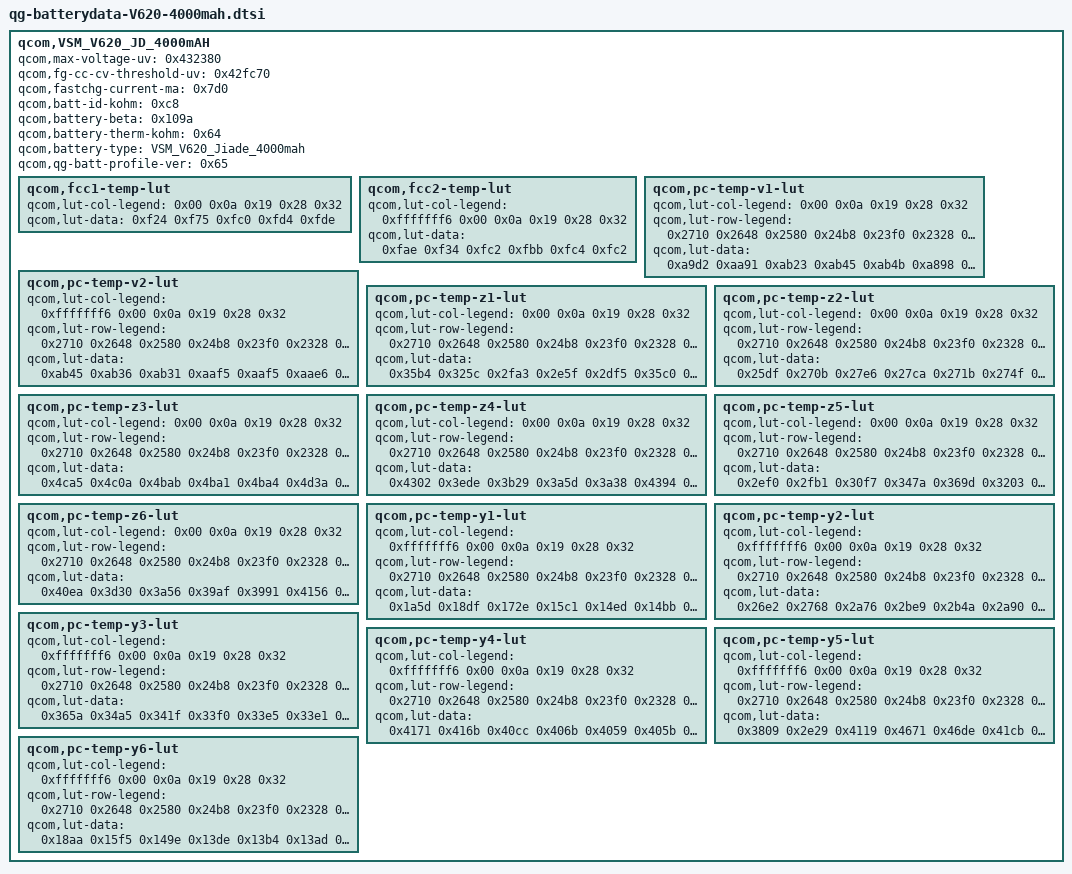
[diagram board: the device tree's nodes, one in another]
qcom,VSM_V620_JD_4000mAH {
	qcom,max-voltage-uv = <0x432380>;
	qcom,fg-cc-cv-threshold-uv = <0x42fc70>;
	qcom,fastchg-current-ma = <0x7d0>;
	qcom,batt-id-kohm = <0xc8>;
	qcom,battery-beta = <0x109a>;
	qcom,battery-therm-kohm = <0x64>;
	qcom,battery-type = "VSM_V620_Jiade_4000mah";
	qcom,qg-batt-profile-ver = <0x65>;

	qcom,fcc1-temp-lut {
		qcom,lut-col-legend = <0x00 0x0a 0x19 0x28 0x32>;
		qcom,lut-data = <0xf24 0xf75 0xfc0 0xfd4 0xfde>;
	};

	qcom,fcc2-temp-lut {
		qcom,lut-col-legend = <0xfffffff6 0x00 0x0a 0x19 0x28 0x32>;
		qcom,lut-data = <0xfae 0xf34 0xfc2 0xfbb 0xfc4 0xfc2>;
	};

	qcom,pc-temp-v1-lut {
		qcom,lut-col-legend = <0x00 0x0a 0x19 0x28 0x32>;
		qcom,lut-row-legend = <0x2710 0x2648 0x2580 0x24b8 0x23f0 0x2328 0x2260 0x2198 0x20d0 0x2008 0x1f40 0x1e78 0x1db0 0x1ce8 0x1c20 0x1b58 0x1a90 0x19c8 0x1900 0x1838 0x1770 0x16a8 0x15e0 0x1518 0x1450 0x1388 0x12c0 0x11f8 0x1130 0x1068 0xfa0 0xed8 0xe10 0xd48 0xc80 0xbb8 0xaf0 0xa28 0x960 0x898 0x7d0 0x708 0x640 0x578 0x4b0 0x3e8 0x384 0x320 0x2bc 0x258 0x1f4 0x190 0x12c 0xc8 0x64 0x00>;
		qcom,lut-data = <0xa9d2 0xaa91 0xab23 0xab45 0xab4b 0xa898 0xa95b 0xa9ce 0xa9e6 0xa9e6 0xa78e 0xa83d 0xa8b3 0xa8c9 0xa8ca 0xa69d 0xa73a 0xa7ab 0xa7c5 0xa7c7 0xa5b4 0xa647 0xa6af 0xa6c9 0xa6cc 0xa4d1 0xa55a 0xa5bd 0xa5d8 0xa5db 0xa3f6 0xa471 0xa4ce 0xa4eb 0xa4f0 0xa31e 0xa390 0xa3e1 0xa3ff 0xa406 0xa24b 0xa2b4 0xa2fb 0xa319 0xa321 0xa188 0xa1e0 0xa218 0xa238 0xa23f 0xa0e0 0xa11e 0xa13d 0xa15b 0xa15f 0xa032 0xa078 0xa07a 0xa085 0xa088 0x9f4b 0x9fc4 0x9fcb 0x9fb7 0x9fb7 0x9e26 0x9ecb 0x9f08 0x9eef 0x9eee 0x9d22 0x9da6 0x9e0e 0x9e25 0x9e29 0x9c65 0x9cca 0x9d18 0x9d62 0x9d6a 0x9bc7 0x9c30 0x9c6d 0x9cb0 0x9cb6 0x9b43 0x9bab 0x9be6 0x9c0b 0x9c0b 0x9ad2 0x9b2c 0x9b5e 0x9b6c 0x9b67 0x9a64 0x9ab3 0x9ad5 0x9adc 0x9ad4 0x99ed 0x9a35 0x9a43 0x9a4b 0x9a43 0x9974 0x99b4 0x9992 0x9992 0x998d 0x98fe 0x9924 0x98c6 0x98a7 0x98a3 0x988e 0x9856 0x9808 0x97dc 0x97d8 0x9820 0x9759 0x974b 0x9743 0x9744 0x97ad 0x96ae 0x96ae 0x96c4 0x96c8 0x9737 0x964a 0x9653 0x965e 0x965c 0x96c9 0x9603 0x9613 0x960a 0x95fa 0x9662 0x95d1 0x95d3 0x95bb 0x95a4 0x9606 0x95ab 0x9592 0x956e 0x955a 0x95c3 0x9588 0x9557 0x9529 0x9517 0x958b 0x9566 0x951f 0x94ec 0x94d9 0x9562 0x9544 0x94ed 0x94b8 0x94a0 0x9547 0x9524 0x94c1 0x9487 0x946a 0x9532 0x9508 0x94a0 0x945c 0x943a 0x951a 0x94e9 0x947e 0x9433 0x940b 0x9500 0x94cb 0x945a 0x9407 0x93d8 0x94df 0x94a7 0x9434 0x93d9 0x93a4 0x94b2 0x9474 0x9401 0x939e 0x9362 0x9474 0x942b 0x93b6 0x934c 0x930a 0x9425 0x93d2 0x935c 0x92ec 0x92a6 0x93ac 0x9362 0x92f3 0x9286 0x923d 0x9320 0x92dc 0x9275 0x9210 0x91c4 0x9282 0x923b 0x91d6 0x9172 0x9124 0x91ee 0x91a1 0x9141 0x90e4 0x9097 0x9180 0x9137 0x90d6 0x9084 0x9045 0x915a 0x9110 0x90b5 0x9062 0x9029 0x9143 0x90f8 0x90a0 0x904d 0x9012 0x9129 0x90e5 0x908e 0x903a 0x8ffe 0x9102 0x90c8 0x9070 0x9019 0x8fd5 0x907f 0x903a 0x8fca 0x8f56 0x8ef0 0x8ee2 0x8e98 0x8e2c 0x8db2 0x8d48 0x8cae 0x8c65 0x8bf8 0x8b7c 0x8b12 0x89ae 0x8964 0x88f2 0x8879 0x8808 0x84f4 0x84af 0x8440 0x83d1 0x8353 0x7530 0x7530 0x7530 0x7530 0x7530>;
	};

	qcom,pc-temp-v2-lut {
		qcom,lut-col-legend = <0xfffffff6 0x00 0x0a 0x19 0x28 0x32>;
		qcom,lut-row-legend = <0x2710 0x2648 0x2580 0x24b8 0x23f0 0x2328 0x2260 0x2198 0x20d0 0x2008 0x1f40 0x1e78 0x1db0 0x1ce8 0x1c20 0x1b58 0x1a90 0x19c8 0x1900 0x1838 0x1770 0x16a8 0x15e0 0x1518 0x1450 0x1388 0x12c0 0x11f8 0x1130 0x1068 0xfa0 0xed8 0xe10 0xd48 0xc80 0xbb8 0xaf0 0xa28 0x960 0x898 0x7d0 0x708 0x640 0x578 0x4b0 0x3e8 0x384 0x320 0x2bc 0x258 0x1f4 0x190 0x12c 0xc8 0x64 0x00>;
		qcom,lut-data = <0xab45 0xab36 0xab31 0xaaf5 0xaaf5 0xaae6 0xa97d 0xa997 0xa9af 0xa982 0xa98a 0xa97f 0xa7ee 0xa82a 0xa857 0xa835 0xa843 0xa83c 0xa6a0 0xa6f8 0xa730 0xa715 0xa727 0xa721 0xa584 0xa5f7 0xa632 0xa61e 0xa62f 0xa62b 0xa48d 0xa509 0xa53f 0xa530 0xa541 0xa53d 0xa3c0 0xa41d 0xa44c 0xa442 0xa452 0xa44f 0xa303 0xa33a 0xa360 0xa358 0xa369 0xa365 0xa221 0xa258 0xa27c 0xa273 0xa283 0xa27f 0xa115 0xa16d 0xa19c 0xa190 0xa1a0 0xa19d 0xa035 0xa096 0xa0ca 0xa0b7 0xa0c3 0xa0c0 0x9fb0 0x9ffa 0xa016 0x9ff1 0x9fed 0x9fe9 0x9f35 0x9f7f 0x9f64 0x9f2f 0x9f1d 0x9f18 0x9e35 0x9ecf 0x9e84 0x9e56 0x9e53 0x9e4e 0x9c4a 0x9dad 0x9d75 0x9d66 0x9d8e 0x9d8b 0x9ad2 0x9c78 0x9c90 0x9c96 0x9cd3 0x9cd0 0x9a32 0x9b8d 0x9be9 0x9bf7 0x9c23 0x9c1f 0x99b6 0x9adf 0x9b4f 0x9b68 0x9b7b 0x9b75 0x9913 0x9a33 0x9a9b 0x9ad9 0x9adc 0x9ad6 0x9851 0x995b 0x99d3 0x9a4e 0x9a49 0x9a40 0x979f 0x982c 0x990e 0x99ad 0x99a5 0x999e 0x9705 0x96fb 0x9847 0x98ce 0x98e3 0x98e4 0x967b 0x963c 0x978d 0x97e5 0x981a 0x9822 0x9603 0x95c9 0x96f2 0x972e 0x975c 0x9764 0x9596 0x9558 0x9669 0x968f 0x96a4 0x96a7 0x953d 0x94f9 0x95f1 0x960c 0x9613 0x9612 0x94f8 0x94b9 0x9587 0x95a2 0x95a6 0x95a4 0x94bc 0x9497 0x9526 0x9546 0x954a 0x9547 0x9484 0x9461 0x94c9 0x94f1 0x94f6 0x94ef 0x9451 0x9436 0x9470 0x94a5 0x94aa 0x94a0 0x9421 0x940f 0x942c 0x945f 0x9468 0x945b 0x93f2 0x93ec 0x93f8 0x941e 0x942e 0x9420 0x93c5 0x93ca 0x93cd 0x93e5 0x93f6 0x93e7 0x9393 0x93a9 0x93aa 0x93b3 0x93bc 0x93ab 0x9361 0x9389 0x938e 0x9389 0x9382 0x936d 0x932c 0x9363 0x936c 0x935c 0x9340 0x9325 0x92f3 0x9335 0x9349 0x932e 0x92f6 0x92cb 0x92b8 0x92fd 0x9320 0x92fc 0x92a8 0x9270 0x9278 0x92bb 0x92ea 0x92bb 0x925d 0x921f 0x9236 0x9270 0x92a7 0x926e 0x9212 0x91d3 0x91f3 0x921f 0x9256 0x921c 0x91c4 0x9183 0x91ae 0x91c0 0x91ec 0x91c3 0x9171 0x9133 0x9166 0x915c 0x9175 0x9157 0x9107 0x90c7 0x911e 0x90f5 0x90f2 0x90c9 0x9077 0x9032 0x90cd 0x908f 0x9083 0x904b 0x9006 0x8fce 0x9068 0x9029 0x901b 0x9004 0x8fc8 0x8f92 0x902d 0x8ffb 0x8ffd 0x8ff5 0x8fbc 0x8f88 0x8fe8 0x8fcc 0x8fdb 0x8fe7 0x8fb0 0x8f7a 0x8f93 0x8f91 0x8fa4 0x8fcc 0x8f9a 0x8f62 0x8f06 0x8f2f 0x8f55 0x8f92 0x8f5d 0x8f1a 0x8e10 0x8e62 0x8e99 0x8eb1 0x8e58 0x8df1 0x8c70 0x8ccc 0x8ce7 0x8cee 0x8c7c 0x8c0a 0x8a02 0x8a67 0x8a71 0x8a83 0x8a03 0x8981 0x86a7 0x8706 0x8721 0x8749 0x86b6 0x861f 0x81b8 0x8212 0x822e 0x827f 0x81fb 0x8145 0x70a3 0x6f54 0x6f5b 0x6f90 0x720a 0x70b1>;
	};

	qcom,pc-temp-z1-lut {
		qcom,lut-col-legend = <0x00 0x0a 0x19 0x28 0x32>;
		qcom,lut-row-legend = <0x2710 0x2648 0x2580 0x24b8 0x23f0 0x2328 0x2260 0x2198 0x20d0 0x2008 0x1f40 0x1e78 0x1db0 0x1ce8 0x1c20 0x1b58 0x1a90 0x19c8 0x1900 0x1838 0x1770 0x16a8 0x15e0 0x1518 0x1450 0x1388 0x12c0 0x11f8 0x1130 0x1068 0xfa0 0xed8 0xe10 0xd48 0xc80 0xbb8 0xaf0 0xa28 0x960 0x898 0x7d0 0x708 0x640 0x578 0x4b0 0x3e8 0x384 0x320 0x2bc 0x258 0x1f4 0x190 0x12c 0xc8 0x64 0x00>;
		qcom,lut-data = <0x35b4 0x325c 0x2fa3 0x2e5f 0x2df5 0x35c0 0x3265 0x2fbe 0x2e97 0x2e31 0x35b8 0x326c 0x2fbf 0x2e97 0x2e33 0x35b1 0x3272 0x2fbe 0x2e93 0x2e32 0x35b0 0x3277 0x2fb9 0x2e8c 0x2e30 0x35af 0x3272 0x2fb2 0x2e83 0x2e2d 0x35ae 0x325c 0x2fb3 0x2e7d 0x2e2a 0x35a4 0x3248 0x2fb8 0x2e7a 0x2e29 0x358e 0x323e 0x2fbb 0x2e78 0x2e28 0x3582 0x3236 0x2faa 0x2e77 0x2e27 0x3587 0x322f 0x2f97 0x2e75 0x2e25 0x358f 0x3226 0x2f92 0x2e74 0x2e24 0x357f 0x321e 0x2f8f 0x2e72 0x2e23 0x3543 0x3210 0x2f8b 0x2e70 0x2e23 0x3518 0x31f7 0x2f7f 0x2e6f 0x2e23 0x350c 0x31ed 0x2f74 0x2e6e 0x2e24 0x3505 0x31ef 0x2f74 0x2e6e 0x2e25 0x3502 0x31f3 0x2f7b 0x2e70 0x2e26 0x34fc 0x31fc 0x2f81 0x2e71 0x2e28 0x34f6 0x3209 0x2f89 0x2e74 0x2e29 0x34ef 0x3213 0x2f8f 0x2e77 0x2e2b 0x34ea 0x321c 0x2f91 0x2e78 0x2e2c 0x34f0 0x3222 0x2f91 0x2e79 0x2e2e 0x3502 0x3223 0x2f92 0x2e7a 0x2e30 0x3517 0x3225 0x2f95 0x2e7c 0x2e31 0x3526 0x3227 0x2f99 0x2e7f 0x2e33 0x3535 0x3229 0x2f9d 0x2e83 0x2e35 0x353e 0x322d 0x2fa0 0x2e87 0x2e3a 0x3538 0x3236 0x2fa4 0x2e8b 0x2e3e 0x3530 0x3246 0x2fa8 0x2e8e 0x2e41 0x353d 0x324e 0x2fac 0x2e91 0x2e43 0x3560 0x324f 0x2fb1 0x2e95 0x2e46 0x3572 0x3251 0x2fb6 0x2e99 0x2e49 0x3568 0x3254 0x2fbc 0x2e9d 0x2e4d 0x355c 0x325a 0x2fc5 0x2ea1 0x2e51 0x3561 0x3261 0x2fcc 0x2ea6 0x2e55 0x3583 0x327a 0x2fd1 0x2eab 0x2e58 0x35a3 0x3295 0x2fd5 0x2eaf 0x2e5b 0x35b4 0x329c 0x2fda 0x2eb4 0x2e5f 0x35c0 0x329d 0x2fdf 0x2eb9 0x2e63 0x35c8 0x32a1 0x2fe5 0x2ebd 0x2e66 0x35ca 0x32b3 0x2fee 0x2ec1 0x2e6a 0x35cc 0x32c0 0x2ff7 0x2ec4 0x2e6d 0x35cd 0x32b8 0x2ffa 0x2eca 0x2e70 0x35db 0x32c4 0x3001 0x2ecf 0x2e73 0x35ff 0x32cb 0x300d 0x2ed2 0x2e75 0x35d9 0x32be 0x3006 0x2ecf 0x2e76 0x35e1 0x32b3 0x300f 0x2ed0 0x2e76 0x35e6 0x32b6 0x3011 0x2ed3 0x2e78 0x3603 0x32ca 0x3013 0x2edc 0x2e7e 0x35d7 0x32ea 0x301b 0x2ee2 0x2e85 0x3621 0x32d6 0x3027 0x2eed 0x2e8d 0x360b 0x3305 0x303d 0x2ef4 0x2e96 0x3647 0x3332 0x3050 0x2f0b 0x2ea5 0x3647 0x3332 0x3050 0x2f0b 0x2ea5 0x3647 0x3332 0x3050 0x2f0b 0x2ea5>;
	};

	qcom,pc-temp-z2-lut {
		qcom,lut-col-legend = <0x00 0x0a 0x19 0x28 0x32>;
		qcom,lut-row-legend = <0x2710 0x2648 0x2580 0x24b8 0x23f0 0x2328 0x2260 0x2198 0x20d0 0x2008 0x1f40 0x1e78 0x1db0 0x1ce8 0x1c20 0x1b58 0x1a90 0x19c8 0x1900 0x1838 0x1770 0x16a8 0x15e0 0x1518 0x1450 0x1388 0x12c0 0x11f8 0x1130 0x1068 0xfa0 0xed8 0xe10 0xd48 0xc80 0xbb8 0xaf0 0xa28 0x960 0x898 0x7d0 0x708 0x640 0x578 0x4b0 0x3e8 0x384 0x320 0x2bc 0x258 0x1f4 0x190 0x12c 0xc8 0x64 0x00>;
		qcom,lut-data = <0x25df 0x270b 0x27e6 0x27ca 0x271b 0x274f 0x2795 0x27e3 0x2821 0x2794 0x27b6 0x27ce 0x2830 0x2829 0x27d4 0x27e5 0x27c3 0x2856 0x2828 0x2803 0x27e9 0x27a3 0x283d 0x2825 0x280f 0x27d6 0x2787 0x2814 0x281d 0x2815 0x27c7 0x276e 0x27f8 0x2814 0x2813 0x27bb 0x275a 0x27df 0x27fc 0x27fb 0x27aa 0x274a 0x27d6 0x27e7 0x27e5 0x279d 0x273d 0x27dc 0x27e5 0x27de 0x2796 0x273a 0x27e6 0x27e9 0x27d2 0x2789 0x273d 0x27ee 0x27ea 0x27ce 0x2774 0x2745 0x27f8 0x27ea 0x27b9 0x2759 0x2754 0x2802 0x27eb 0x27aa 0x2745 0x276c 0x2815 0x27f2 0x27ba 0x273b 0x277f 0x2825 0x27f9 0x27d6 0x2730 0x278b 0x2828 0x27ef 0x27d8 0x272a 0x2797 0x2828 0x27cb 0x27ba 0x272b 0x27ad 0x282b 0x27b5 0x27a5 0x272b 0x27c9 0x2841 0x27c1 0x27aa 0x2724 0x27e8 0x2865 0x27de 0x27b7 0x271d 0x280f 0x2897 0x2825 0x27f5 0x271a 0x282e 0x28db 0x28ec 0x28dd 0x2720 0x2837 0x28ed 0x2954 0x2964 0x272d 0x2836 0x28a9 0x28d3 0x28f0 0x273e 0x2836 0x2865 0x282c 0x284f 0x2756 0x283d 0x2866 0x282e 0x2861 0x276a 0x2845 0x2874 0x2881 0x2903 0x277c 0x284f 0x287b 0x28ae 0x2954 0x278c 0x285c 0x287f 0x2896 0x28ca 0x2799 0x2861 0x2882 0x286e 0x2809 0x27a9 0x2866 0x2886 0x2849 0x27b2 0x27b5 0x286c 0x288e 0x2812 0x2778 0x27bb 0x286f 0x288f 0x27fb 0x2766 0x27c0 0x2878 0x288b 0x2801 0x276b 0x27c9 0x287f 0x288a 0x280d 0x2774 0x27d9 0x288a 0x2892 0x281a 0x2797 0x27ee 0x289b 0x289f 0x2830 0x27e2 0x280a 0x28ac 0x28af 0x284d 0x280f 0x282d 0x28be 0x28c7 0x2884 0x282a 0x2848 0x28ca 0x28d6 0x28ab 0x2839 0x2859 0x28d2 0x28d6 0x289a 0x2831 0x2870 0x28d9 0x28d6 0x287c 0x2823 0x2894 0x28dd 0x28d4 0x289e 0x2865 0x2977 0x2948 0x28ed 0x289e 0x287c 0x29ca 0x298b 0x28f6 0x2864 0x2835 0x29a1 0x298d 0x28e2 0x285f 0x2831 0x278f 0x29a5 0x28f9 0x2861 0x2834 0x2710 0x29e8 0x28f6 0x2879 0x284e 0x2734 0x2c60 0x2912 0x28cf 0x28b9 0x280e 0x2b7d 0x2917 0x2874 0x2842 0x2840 0x29ca 0x28c5 0x27f1 0x279d 0x276a 0x292e 0x28af 0x27be 0x2750 0x27d0 0x28c4 0x2861 0x2781 0x271c 0x27d0 0x28c4 0x2861 0x2781 0x271c 0x27d0 0x28c4 0x2861 0x2781 0x271c>;
	};

	qcom,pc-temp-z3-lut {
		qcom,lut-col-legend = <0x00 0x0a 0x19 0x28 0x32>;
		qcom,lut-row-legend = <0x2710 0x2648 0x2580 0x24b8 0x23f0 0x2328 0x2260 0x2198 0x20d0 0x2008 0x1f40 0x1e78 0x1db0 0x1ce8 0x1c20 0x1b58 0x1a90 0x19c8 0x1900 0x1838 0x1770 0x16a8 0x15e0 0x1518 0x1450 0x1388 0x12c0 0x11f8 0x1130 0x1068 0xfa0 0xed8 0xe10 0xd48 0xc80 0xbb8 0xaf0 0xa28 0x960 0x898 0x7d0 0x708 0x640 0x578 0x4b0 0x3e8 0x384 0x320 0x2bc 0x258 0x1f4 0x190 0x12c 0xc8 0x64 0x00>;
		qcom,lut-data = <0x4ca5 0x4c0a 0x4bab 0x4ba1 0x4ba4 0x4d3a 0x4c85 0x4c04 0x4bd5 0x4bc4 0x4d38 0x4cc5 0x4c20 0x4be3 0x4bd2 0x4d22 0x4cd1 0x4c29 0x4bea 0x4bd9 0x4d04 0x4cd7 0x4c29 0x4bf0 0x4be0 0x4cdd 0x4cd7 0x4c27 0x4bf4 0x4be6 0x4cc6 0x4cd3 0x4c25 0x4bf5 0x4be7 0x4cc6 0x4ccc 0x4c22 0x4bf3 0x4be5 0x4ccd 0x4cc4 0x4c1f 0x4bf0 0x4be1 0x4cd6 0x4cba 0x4c1a 0x4be9 0x4bdc 0x4cdf 0x4cad 0x4c13 0x4bdf 0x4bd7 0x4ce9 0x4c99 0x4c07 0x4bd8 0x4bd2 0x4cfd 0x4c89 0x4bf4 0x4bd2 0x4bcc 0x4d23 0x4c86 0x4bec 0x4bce 0x4bc7 0x4d39 0x4c88 0x4bf6 0x4bcd 0x4bc4 0x4d2a 0x4c85 0x4c01 0x4bcd 0x4bc1 0x4d09 0x4c75 0x4bfe 0x4bca 0x4bbd 0x4cee 0x4c60 0x4bf0 0x4bc1 0x4bb8 0x4cd6 0x4c52 0x4be5 0x4bb9 0x4bb3 0x4cc8 0x4c46 0x4bdd 0x4bb3 0x4bad 0x4cc9 0x4c41 0x4bd8 0x4bae 0x4ba7 0x4cce 0x4c3f 0x4bde 0x4bb1 0x4ba8 0x4cd2 0x4c3d 0x4bef 0x4bc2 0x4bb3 0x4cd7 0x4c45 0x4bf5 0x4bca 0x4bba 0x4cdb 0x4c56 0x4bed 0x4bbb 0x4bad 0x4cdf 0x4c5d 0x4be3 0x4ba7 0x4b9b 0x4ce7 0x4c5b 0x4be1 0x4ba9 0x4ba4 0x4cec 0x4c59 0x4bdf 0x4bb9 0x4bd1 0x4ced 0x4c57 0x4bdf 0x4bc7 0x4be7 0x4cec 0x4c54 0x4bea 0x4bd4 0x4be1 0x4ce8 0x4c52 0x4bf5 0x4bdd 0x4bd6 0x4ce3 0x4c51 0x4bf8 0x4bdc 0x4bce 0x4cdc 0x4c4f 0x4bfb 0x4bd4 0x4bc6 0x4cd1 0x4c4e 0x4bfb 0x4bcd 0x4bbe 0x4cc4 0x4c4a 0x4bf5 0x4bc5 0x4bb5 0x4cb7 0x4c46 0x4bed 0x4bbe 0x4bad 0x4ca9 0x4c43 0x4be9 0x4bb8 0x4ba6 0x4c9c 0x4c3f 0x4be5 0x4bb2 0x4ba1 0x4c91 0x4c3c 0x4be1 0x4bb0 0x4b9f 0x4c85 0x4c38 0x4bde 0x4bb0 0x4b9f 0x4c80 0x4c33 0x4bdb 0x4bb1 0x4b9f 0x4c7e 0x4c2e 0x4bd7 0x4bae 0x4b9f 0x4c7c 0x4c29 0x4bd3 0x4bab 0x4ba1 0x4c71 0x4c26 0x4bd3 0x4baf 0x4ba6 0x4c31 0x4c12 0x4bce 0x4bab 0x4ba7 0x4bc9 0x4bf4 0x4bc2 0x4ba2 0x4b9d 0x4bb1 0x4bf2 0x4bc1 0x4b9e 0x4b95 0x4b5b 0x4be6 0x4bb9 0x4b94 0x4b8c 0x4b44 0x4bb5 0x4baa 0x4b90 0x4b87 0x4b47 0x4b77 0x4ba4 0x4b81 0x4b79 0x4b44 0x4b83 0x4ba5 0x4b99 0x4b92 0x4b75 0x4bd7 0x4baa 0x4ba4 0x4ba3 0x4b7d 0x4bca 0x4ba0 0x4ba7 0x4ba0 0x4b99 0x4bc4 0x4ba1 0x4ba6 0x4ba3 0x4b99 0x4bc4 0x4ba1 0x4ba6 0x4ba3 0x4b99 0x4bc4 0x4ba1 0x4ba6 0x4ba3>;
	};

	qcom,pc-temp-z4-lut {
		qcom,lut-col-legend = <0x00 0x0a 0x19 0x28 0x32>;
		qcom,lut-row-legend = <0x2710 0x2648 0x2580 0x24b8 0x23f0 0x2328 0x2260 0x2198 0x20d0 0x2008 0x1f40 0x1e78 0x1db0 0x1ce8 0x1c20 0x1b58 0x1a90 0x19c8 0x1900 0x1838 0x1770 0x16a8 0x15e0 0x1518 0x1450 0x1388 0x12c0 0x11f8 0x1130 0x1068 0xfa0 0xed8 0xe10 0xd48 0xc80 0xbb8 0xaf0 0xa28 0x960 0x898 0x7d0 0x708 0x640 0x578 0x4b0 0x3e8 0x384 0x320 0x2bc 0x258 0x1f4 0x190 0x12c 0xc8 0x64 0x00>;
		qcom,lut-data = <0x4302 0x3ede 0x3b29 0x3a5d 0x3a38 0x4394 0x3e16 0x3be0 0x3ab7 0x3a60 0x4248 0x3d52 0x3b42 0x3a7e 0x3a42 0x409a 0x3c7e 0x3ab4 0x3a36 0x3a15 0x3f66 0x3bb4 0x3a68 0x3a0b 0x39f4 0x3e88 0x3b31 0x3a2d 0x39e6 0x39d7 0x3dd3 0x3ad1 0x3a01 0x39c9 0x39be 0x3d3b 0x3a88 0x39de 0x39ae 0x39a7 0x3cb9 0x3a54 0x39c4 0x399c 0x3996 0x3c42 0x3a2a 0x39b0 0x3995 0x3990 0x3bcd 0x3a04 0x39a1 0x3990 0x398c 0x3b67 0x39db 0x3995 0x3989 0x3987 0x3b1b 0x39c0 0x398b 0x3982 0x3982 0x3ae0 0x39bb 0x3988 0x397b 0x397d 0x3ab2 0x39bb 0x3989 0x3976 0x3978 0x3a91 0x39b8 0x398b 0x3970 0x3973 0x3a75 0x39ab 0x3984 0x396d 0x396f 0x3a58 0x399a 0x3970 0x3969 0x396b 0x3a3d 0x398e 0x3966 0x3965 0x3966 0x3a25 0x3983 0x3962 0x395f 0x395f 0x3a0e 0x397e 0x3961 0x3959 0x3958 0x39f5 0x397b 0x396a 0x3962 0x3961 0x39e1 0x397a 0x3989 0x3994 0x3996 0x39d0 0x399d 0x39ac 0x39c1 0x39c4 0x39c2 0x39f8 0x39e4 0x39e5 0x39e0 0x39ba 0x3a22 0x3a0f 0x3a01 0x39f6 0x39ba 0x3a25 0x3a0a 0x39fa 0x39e8 0x39c1 0x3a21 0x39f2 0x39d4 0x39a6 0x39cc 0x3a14 0x39da 0x39b1 0x397f 0x39d8 0x39fa 0x39bf 0x3996 0x3977 0x39db 0x39e2 0x39a6 0x3980 0x3973 0x39d7 0x39ce 0x3996 0x3976 0x396e 0x39d0 0x39bc 0x3989 0x3970 0x396a 0x39c5 0x39ac 0x3980 0x396c 0x3966 0x39b8 0x399e 0x397a 0x3969 0x3964 0x39ad 0x3992 0x3976 0x3967 0x3962 0x39a5 0x3987 0x3973 0x3967 0x3962 0x399e 0x397f 0x3971 0x3967 0x3962 0x3996 0x397d 0x3971 0x3967 0x3964 0x398f 0x397c 0x3974 0x396f 0x396f 0x398b 0x397b 0x3976 0x3975 0x3979 0x3989 0x3978 0x3972 0x3971 0x3973 0x3986 0x3975 0x396b 0x3968 0x3969 0x3981 0x396f 0x3967 0x3967 0x396a 0x3984 0x395f 0x395a 0x3961 0x3962 0x39d7 0x395d 0x394c 0x394d 0x394c 0x39ec 0x3958 0x3945 0x394a 0x3949 0x3a43 0x395a 0x393f 0x3943 0x3942 0x3a53 0x3987 0x3941 0x3934 0x392f 0x3a4a 0x39c6 0x393e 0x3934 0x392a 0x3a47 0x39bc 0x394b 0x3936 0x393d 0x3a35 0x3978 0x395b 0x3947 0x3948 0x3a46 0x3993 0x396d 0x394a 0x3951 0x3a41 0x39a8 0x3972 0x3950 0x3953 0x3a41 0x39a8 0x3972 0x3950 0x3953 0x3a41 0x39a8 0x3972 0x3950 0x3953>;
	};

	qcom,pc-temp-z5-lut {
		qcom,lut-col-legend = <0x00 0x0a 0x19 0x28 0x32>;
		qcom,lut-row-legend = <0x2710 0x2648 0x2580 0x24b8 0x23f0 0x2328 0x2260 0x2198 0x20d0 0x2008 0x1f40 0x1e78 0x1db0 0x1ce8 0x1c20 0x1b58 0x1a90 0x19c8 0x1900 0x1838 0x1770 0x16a8 0x15e0 0x1518 0x1450 0x1388 0x12c0 0x11f8 0x1130 0x1068 0xfa0 0xed8 0xe10 0xd48 0xc80 0xbb8 0xaf0 0xa28 0x960 0x898 0x7d0 0x708 0x640 0x578 0x4b0 0x3e8 0x384 0x320 0x2bc 0x258 0x1f4 0x190 0x12c 0xc8 0x64 0x00>;
		qcom,lut-data = <0x2ef0 0x2fb1 0x30f7 0x347a 0x369d 0x3203 0x343b 0x3a24 0x3de1 0x3e20 0x3337 0x37cf 0x3e47 0x4237 0x437a 0x33ef 0x3a5f 0x4150 0x455c 0x478e 0x3486 0x3c82 0x43c9 0x4930 0x4cbc 0x34fc 0x3edc 0x45f4 0x4d31 0x522f 0x3576 0x4175 0x4897 0x512e 0x56a1 0x3626 0x4411 0x4baf 0x55db 0x5a79 0x3734 0x469c 0x4ea6 0x5896 0x5d2e 0x386a 0x4910 0x5218 0x57ed 0x5e4b 0x3998 0x4af8 0x54c0 0x5670 0x5ec4 0x3b1f 0x4c4a 0x53b4 0x55a5 0x5ee4 0x3e90 0x4e12 0x4f10 0x56c3 0x5ea9 0x4648 0x5582 0x4d47 0x58b8 0x5ed3 0x4b2f 0x6284 0x5ae9 0x5dd5 0x6150 0x49ac 0x664a 0x6a46 0x645f 0x6595 0x4604 0x5ffc 0x697f 0x64da 0x683a 0x43d8 0x5a0c 0x6321 0x6148 0x6a2d 0x42a6 0x5a5d 0x608f 0x5f14 0x6b49 0x4207 0x5d23 0x6249 0x5fca 0x6ba7 0x4405 0x60e9 0x65ea 0x61aa 0x6ce3 0x4a7a 0x6753 0x79bd 0x6b36 0x72a1 0x516d 0x7108 0xa6ff 0x8bfe 0x8518 0x589d 0x8db6 0xb5dd 0x9d50 0x8f7a 0x6188 0xba03 0x923c 0x7a6a 0x71d7 0x717f 0xc766 0x6a05 0x4d50 0x48e2 0x8ce2 0xb455 0x5c77 0x47f0 0x4942 0x9f24 0x9c42 0x5416 0x4976 0x616c 0xa946 0x8fac 0x527a 0x4c08 0x6e14 0xafdf 0x8651 0x5885 0x5831 0x6d04 0xaf04 0x8131 0x61b0 0x6738 0x6b93 0xacda 0x7fb8 0x6e28 0x6dec 0x6c75 0xa96f 0x8076 0x7e52 0x7250 0x6f37 0x9e81 0x8258 0x8576 0x7562 0x70d3 0x8e17 0x84a1 0x8828 0x77fd 0x6fd8 0x821e 0x8757 0x8970 0x7983 0x6e7a 0x7890 0x8c8d 0x89a4 0x78dc 0x6e34 0x723f 0x91c8 0x89be 0x76c6 0x6d91 0x6eb0 0x92d8 0x8934 0x7544 0x6c96 0x6bb7 0x9250 0x83f9 0x754b 0x69cf 0x6b90 0x90c7 0x7cdd 0x7495 0x66c4 0x741a 0x86be 0x73bf 0x6c39 0x6441 0x7948 0x7fa7 0x6c9d 0x61c6 0x6234 0x765b 0x816b 0x6ff6 0x6b40 0x6ea3 0x5f7c 0x7f41 0x71f1 0x6afe 0x76f2 0x4247 0x63af 0x6a75 0x6016 0x6576 0x3c38 0x62bf 0x6af3 0x5a93 0x56de 0x2e88 0x578e 0x60e6 0x5131 0x4ea2 0x2d0a 0x40e2 0x50d6 0x5522 0x561a 0x2d2a 0x3253 0x4e4f 0x4932 0x4dc6 0x2d86 0x33ca 0x4ad0 0x6598 0x6f2f 0x312f 0x46cf 0x4548 0x525d 0x58e7 0x302e 0x425f 0x3d0a 0x4d75 0x49ed 0x3067 0x3af8 0x3b42 0x4599 0x43f4 0x3067 0x3af8 0x3b42 0x4599 0x43f4 0x3067 0x3af8 0x3b42 0x4599 0x43f4>;
	};

	qcom,pc-temp-z6-lut {
		qcom,lut-col-legend = <0x00 0x0a 0x19 0x28 0x32>;
		qcom,lut-row-legend = <0x2710 0x2648 0x2580 0x24b8 0x23f0 0x2328 0x2260 0x2198 0x20d0 0x2008 0x1f40 0x1e78 0x1db0 0x1ce8 0x1c20 0x1b58 0x1a90 0x19c8 0x1900 0x1838 0x1770 0x16a8 0x15e0 0x1518 0x1450 0x1388 0x12c0 0x11f8 0x1130 0x1068 0xfa0 0xed8 0xe10 0xd48 0xc80 0xbb8 0xaf0 0xa28 0x960 0x898 0x7d0 0x708 0x640 0x578 0x4b0 0x3e8 0x384 0x320 0x2bc 0x258 0x1f4 0x190 0x12c 0xc8 0x64 0x00>;
		qcom,lut-data = <0x40ea 0x3d30 0x3a56 0x39af 0x3991 0x4156 0x3cfe 0x3acd 0x39f5 0x39b7 0x40b4 0x3cc6 0x3a98 0x39e3 0x39af 0x3fc2 0x3c6c 0x3a63 0x39cb 0x39a4 0x3f0c 0x3c04 0x3a40 0x39bb 0x399a 0x3e84 0x3bbd 0x3a21 0x39ac 0x3990 0x3e16 0x3b86 0x3a0b 0x399f 0x3986 0x3dc4 0x3b5a 0x39f8 0x3993 0x397b 0x3d82 0x3b37 0x39e9 0x3989 0x3972 0x3d45 0x3b1a 0x39dd 0x3980 0x396c 0x3d09 0x3afc 0x39d2 0x3979 0x3967 0x3cd3 0x3ada 0x39c5 0x3972 0x3962 0x3cad 0x3ac0 0x39b5 0x396b 0x395c 0x3c91 0x3ab5 0x39af 0x3966 0x3957 0x3c76 0x3aad 0x39b3 0x3962 0x3953 0x3c55 0x3aa7 0x39b6 0x395f 0x394e 0x3c31 0x3a99 0x39b2 0x395b 0x394a 0x3c14 0x3a8a 0x39a4 0x3955 0x3946 0x3bfe 0x3a80 0x399a 0x394f 0x3941 0x3bf0 0x3a79 0x3996 0x3949 0x393b 0x3bec 0x3a76 0x3993 0x3944 0x3934 0x3be9 0x3a76 0x399a 0x394b 0x3939 0x3be9 0x3a76 0x39b0 0x396b 0x3957 0x3be9 0x3a8a 0x39c4 0x3981 0x396d 0x3be9 0x3abb 0x39d9 0x3988 0x3972 0x3bec 0x3ad1 0x39e6 0x398c 0x3975 0x3bf3 0x3ad3 0x39e4 0x398a 0x3973 0x3bfa 0x3ad2 0x39da 0x3983 0x3970 0x3c03 0x3acd 0x39d2 0x397d 0x396c 0x3c0a 0x3ac2 0x39cd 0x3979 0x3967 0x3c0c 0x3ab9 0x39c8 0x3975 0x3960 0x3c0a 0x3ab2 0x39c4 0x3970 0x395a 0x3c07 0x3aab 0x39c1 0x396a 0x3954 0x3c00 0x3aa5 0x39bd 0x3965 0x394e 0x3bf7 0x3aa0 0x39b8 0x3960 0x3949 0x3bef 0x3a9c 0x39b4 0x395c 0x3944 0x3bea 0x3a99 0x39b2 0x3959 0x3940 0x3be6 0x3a97 0x39b0 0x3956 0x393d 0x3be3 0x3a97 0x39af 0x3955 0x393d 0x3be2 0x3a98 0x39b1 0x3959 0x3942 0x3be2 0x3a99 0x39b1 0x395c 0x3946 0x3be7 0x3a9a 0x39af 0x3959 0x3944 0x3beb 0x3a9b 0x39ac 0x3955 0x3941 0x3beb 0x3a9c 0x39ac 0x3957 0x3945 0x3bd6 0x3a94 0x39a6 0x3954 0x3942 0x3bcb 0x3a85 0x399b 0x3947 0x3934 0x3bc9 0x3a84 0x3998 0x3944 0x392f 0x3bc3 0x3a7f 0x3992 0x393c 0x3927 0x3bbf 0x3a7b 0x398c 0x3933 0x391d 0x3bbe 0x3a79 0x3989 0x392c 0x3913 0x3bc7 0x3a80 0x3992 0x393b 0x392a 0x3bdb 0x3a95 0x39a0 0x394b 0x393a 0x3bf0 0x3aa3 0x39a7 0x3951 0x3940 0x3c10 0x3ab9 0x39b1 0x3957 0x3946 0x3c10 0x3ab9 0x39b1 0x3957 0x3946 0x3c10 0x3ab9 0x39b1 0x3957 0x3946>;
	};

	qcom,pc-temp-y1-lut {
		qcom,lut-col-legend = <0xfffffff6 0x00 0x0a 0x19 0x28 0x32>;
		qcom,lut-row-legend = <0x2710 0x2648 0x2580 0x24b8 0x23f0 0x2328 0x2260 0x2198 0x20d0 0x2008 0x1f40 0x1e78 0x1db0 0x1ce8 0x1c20 0x1b58 0x1a90 0x19c8 0x1900 0x1838 0x1770 0x16a8 0x15e0 0x1518 0x1450 0x1388 0x12c0 0x11f8 0x1130 0x1068 0xfa0 0xed8 0xe10 0xd48 0xc80 0xbb8 0xaf0 0xa28 0x960 0x898 0x7d0 0x708 0x640 0x578 0x4b0 0x3e8 0x384 0x320 0x2bc 0x258 0x1f4 0x190 0x12c 0xc8 0x64 0x00>;
		qcom,lut-data = <0x1a5d 0x18df 0x172e 0x15c1 0x14ed 0x14bb 0x1aa0 0x18d2 0x172d 0x15bc 0x14f0 0x14ba 0x1ad1 0x18c5 0x172c 0x15b7 0x14f2 0x14b9 0x1af1 0x18b9 0x172b 0x15b2 0x14f3 0x14b8 0x1b03 0x18b1 0x172a 0x15ad 0x14f3 0x14b8 0x1b09 0x18ac 0x1729 0x15a9 0x14f3 0x14b7 0x1afa 0x18af 0x1728 0x15a4 0x14f1 0x14b6 0x1ae1 0x18b4 0x1727 0x159f 0x14ef 0x14b5 0x1ad2 0x18b3 0x1725 0x159e 0x14ed 0x14b5 0x1ac6 0x18ab 0x1721 0x159d 0x14ec 0x14b5 0x1ac1 0x18a7 0x171e 0x159c 0x14ea 0x14b4 0x1ad3 0x18a8 0x171b 0x1597 0x14e8 0x14b3 0x1aee 0x18ad 0x1719 0x1592 0x14e5 0x14b3 0x1af5 0x18b4 0x1719 0x1592 0x14e5 0x14b2 0x1af3 0x18bd 0x171a 0x1594 0x14e7 0x14b3 0x1af0 0x18c3 0x171a 0x1597 0x14e8 0x14b3 0x1ae1 0x18c5 0x171a 0x1599 0x14e8 0x14b4 0x1ace 0x18c3 0x171c 0x159c 0x14e8 0x14b4 0x1acd 0x18c0 0x171e 0x159c 0x14e8 0x14b4 0x1ad9 0x18c1 0x1721 0x159d 0x14e9 0x14b5 0x1ae0 0x18c8 0x1726 0x159d 0x14ea 0x14b5 0x1ada 0x18d1 0x172e 0x159e 0x14eb 0x14b6 0x1ad2 0x18d3 0x1736 0x15a0 0x14ed 0x14b7 0x1ad6 0x18c3 0x1735 0x15a2 0x14ee 0x14b8 0x1ae2 0x18c5 0x1732 0x15a5 0x14ef 0x14ba 0x1ae9 0x18c9 0x1731 0x15a8 0x14f1 0x14bc 0x1ae8 0x18cc 0x1731 0x15ab 0x14f3 0x14be 0x1ae6 0x18d1 0x1731 0x15ae 0x14f6 0x14c1 0x1ae2 0x18ca 0x1731 0x15b1 0x14f9 0x14c3 0x1ad8 0x18c7 0x1733 0x15b4 0x14fb 0x14c5 0x1ad2 0x18c4 0x1734 0x15b8 0x14fe 0x14c8 0x1acb 0x18c6 0x1735 0x15bb 0x1502 0x14ca 0x1ac3 0x18c8 0x1736 0x15be 0x1505 0x14cc 0x1ac1 0x18c2 0x1736 0x15c3 0x1508 0x14cf 0x1ac1 0x18bb 0x1735 0x15c8 0x150b 0x14d3 0x1ac2 0x18bb 0x1736 0x15cb 0x150d 0x14d5 0x1ad1 0x18bf 0x173e 0x15cb 0x1510 0x14d5 0x1ae2 0x18c5 0x1744 0x15cb 0x1512 0x14d6 0x1aea 0x18d1 0x1743 0x15cd 0x1513 0x14d7 0x1af6 0x18e2 0x1740 0x15d1 0x1514 0x14d8 0x1af7 0x18e5 0x1741 0x15d3 0x1516 0x14d9 0x1add 0x18dc 0x1753 0x15d4 0x1519 0x14db 0x1acd 0x18d4 0x1759 0x15d7 0x151b 0x14dd 0x1ac8 0x18d7 0x1751 0x15e5 0x151d 0x14e1 0x1ad4 0x18e3 0x1759 0x15ef 0x1525 0x14e4 0x1b16 0x18fc 0x176b 0x15fe 0x152b 0x14e9 0x1b29 0x1916 0x177f 0x15f8 0x152d 0x14e9 0x1b19 0x1915 0x176a 0x15f8 0x152c 0x14ea 0x1b4f 0x1900 0x1784 0x1600 0x152a 0x14e8 0x1b4f 0x1927 0x1772 0x1603 0x1529 0x14e9 0x1b38 0x191a 0x177a 0x1601 0x152c 0x14eb 0x1b44 0x191c 0x1786 0x1609 0x1532 0x14f1 0x1b4b 0x1944 0x1790 0x1626 0x153f 0x14f9 0x1bad 0x1959 0x17b4 0x1641 0x1558 0x1504 0x1bad 0x1959 0x17b4 0x1641 0x1558 0x1504 0x1bad 0x1959 0x17b4 0x1641 0x1558 0x1504>;
	};

	qcom,pc-temp-y2-lut {
		qcom,lut-col-legend = <0xfffffff6 0x00 0x0a 0x19 0x28 0x32>;
		qcom,lut-row-legend = <0x2710 0x2648 0x2580 0x24b8 0x23f0 0x2328 0x2260 0x2198 0x20d0 0x2008 0x1f40 0x1e78 0x1db0 0x1ce8 0x1c20 0x1b58 0x1a90 0x19c8 0x1900 0x1838 0x1770 0x16a8 0x15e0 0x1518 0x1450 0x1388 0x12c0 0x11f8 0x1130 0x1068 0xfa0 0xed8 0xe10 0xd48 0xc80 0xbb8 0xaf0 0xa28 0x960 0x898 0x7d0 0x708 0x640 0x578 0x4b0 0x3e8 0x384 0x320 0x2bc 0x258 0x1f4 0x190 0x12c 0xc8 0x64 0x00>;
		qcom,lut-data = <0x26e2 0x2768 0x2a76 0x2be9 0x2b4a 0x2a90 0x26bc 0x2799 0x2a69 0x2bbc 0x2b2b 0x2a90 0x26b0 0x27cf 0x2a55 0x2b90 0x2b01 0x2a81 0x26b9 0x2805 0x2a3c 0x2b66 0x2ad4 0x2a6c 0x26d1 0x2830 0x2a20 0x2b3c 0x2aaa 0x2a57 0x26f3 0x284b 0x2a02 0x2b14 0x2a8b 0x2a48 0x2737 0x284e 0x29db 0x2aea 0x2a70 0x2a39 0x2793 0x284a 0x29b6 0x2ac3 0x2a58 0x2a2a 0x27e1 0x2851 0x29a7 0x2aa6 0x2a4a 0x2a28 0x2835 0x2890 0x299f 0x2a8e 0x2a42 0x2a29 0x2866 0x28ea 0x299f 0x2a78 0x2a39 0x2a29 0x287c 0x2921 0x29c3 0x2a5a 0x2a1c 0x2a18 0x2890 0x2938 0x29fc 0x2a41 0x29fc 0x29fc 0x2899 0x2933 0x2a25 0x2a45 0x29f6 0x29eb 0x28b7 0x2948 0x2a4c 0x2a68 0x29fc 0x29dd 0x28db 0x2986 0x2a75 0x2a92 0x2a0a 0x29d8 0x2909 0x29b3 0x2aa8 0x2ac3 0x2a28 0x29e0 0x292f 0x29c2 0x2ad6 0x2afd 0x2a55 0x29f1 0x28cf 0x29c6 0x2aee 0x2b45 0x2a90 0x2a15 0x2724 0x29c3 0x2b06 0x2b9e 0x2ae7 0x2a61 0x2624 0x29a5 0x2b0f 0x2bc2 0x2b31 0x2ab6 0x260c 0x297f 0x2b09 0x2ba8 0x2b78 0x2b2d 0x25fe 0x2af4 0x2b03 0x2b87 0x2ba8 0x2b89 0x25f1 0x2a17 0x2b06 0x2b85 0x2b89 0x2b68 0x25e3 0x2990 0x2b11 0x2b89 0x2b27 0x2af7 0x25da 0x2982 0x2b1a 0x2b8e 0x2b00 0x2ac8 0x25d8 0x2980 0x2b21 0x2b94 0x2b1f 0x2ac7 0x25d6 0x2c2b 0x2b23 0x2b9c 0x2b41 0x2ac9 0x25d3 0x2981 0x2b1b 0x2baa 0x2b4b 0x2af4 0x25d1 0x296a 0x2b0a 0x2bbe 0x2b5b 0x2b64 0x25ce 0x2954 0x2afd 0x2bc6 0x2b71 0x2b97 0x25cc 0x2939 0x2af2 0x2bc2 0x2ba2 0x2ba0 0x25ca 0x2922 0x2ae3 0x2bbc 0x2bc8 0x2ba5 0x25c8 0x2911 0x2ac4 0x2bb6 0x2bc3 0x2ba5 0x25c6 0x2904 0x2a92 0x2bb0 0x2bb0 0x2ba2 0x25c5 0x28e2 0x2a65 0x2ba7 0x2b9b 0x2b99 0x25c3 0x280a 0x2a40 0x2b95 0x2b82 0x2b7b 0x25c2 0x2717 0x2a19 0x2b7c 0x2b68 0x2b58 0x25c1 0x2666 0x29eb 0x2b5a 0x2b4d 0x2b28 0x25c0 0x25e2 0x29b5 0x2b2e 0x2b30 0x2ae6 0x25bf 0x25d1 0x297a 0x2b0d 0x2b26 0x2ada 0x25be 0x25c9 0x2933 0x2afa 0x2b35 0x2af9 0x25bd 0x25c5 0x28ed 0x2adc 0x2b20 0x2b00 0x25bc 0x25c1 0x28ac 0x2aa2 0x2ac1 0x2ad9 0x25bc 0x25be 0x2872 0x2a30 0x2aa9 0x2a43 0x25bb 0x25bd 0x282e 0x2a43 0x2a4c 0x29e8 0x25bb 0x25bc 0x282f 0x2a23 0x2a52 0x29cf 0x25ba 0x25bc 0x2812 0x2a2f 0x2a61 0x29ea 0x25ba 0x25bb 0x2731 0x2a26 0x2a82 0x2a1f 0x25ba 0x25ba 0x270e 0x2a1a 0x2a99 0x2a2f 0x25b9 0x25ba 0x26f6 0x2a08 0x2a54 0x2a00 0x25b8 0x25b9 0x26cb 0x29c6 0x2a1e 0x2998 0x25b7 0x25b8 0x25f1 0x2974 0x29e9 0x293a 0x25b5 0x25b7 0x25c6 0x2925 0x298f 0x28fe 0x25b5 0x25b7 0x25c6 0x2925 0x298f 0x28fe 0x25b5 0x25b7 0x25c6 0x2925 0x298f 0x28fe>;
	};

	qcom,pc-temp-y3-lut {
		qcom,lut-col-legend = <0xfffffff6 0x00 0x0a 0x19 0x28 0x32>;
		qcom,lut-row-legend = <0x2710 0x2648 0x2580 0x24b8 0x23f0 0x2328 0x2260 0x2198 0x20d0 0x2008 0x1f40 0x1e78 0x1db0 0x1ce8 0x1c20 0x1b58 0x1a90 0x19c8 0x1900 0x1838 0x1770 0x16a8 0x15e0 0x1518 0x1450 0x1388 0x12c0 0x11f8 0x1130 0x1068 0xfa0 0xed8 0xe10 0xd48 0xc80 0xbb8 0xaf0 0xa28 0x960 0x898 0x7d0 0x708 0x640 0x578 0x4b0 0x3e8 0x384 0x320 0x2bc 0x258 0x1f4 0x190 0x12c 0xc8 0x64 0x00>;
		qcom,lut-data = <0x365a 0x34a5 0x341f 0x33f0 0x33e5 0x33e1 0x363e 0x34ad 0x3422 0x33f0 0x33e5 0x33e2 0x3605 0x34b4 0x3424 0x33f1 0x33e5 0x33e2 0x35c3 0x34b8 0x3427 0x33f2 0x33e5 0x33e3 0x358d 0x34b9 0x3429 0x33f3 0x33e6 0x33e4 0x3576 0x34b7 0x342c 0x33f4 0x33e6 0x33e5 0x3575 0x34b2 0x342f 0x33f5 0x33e7 0x33e5 0x3576 0x34aa 0x3431 0x33f5 0x33e8 0x33e6 0x3560 0x34a4 0x3434 0x33f6 0x33e9 0x33e7 0x34fb 0x34a0 0x3437 0x33f7 0x33e9 0x33e8 0x34be 0x349a 0x3438 0x33f8 0x33ea 0x33e8 0x34c0 0x3489 0x3439 0x33fa 0x33eb 0x33e9 0x34c3 0x3474 0x3438 0x33fd 0x33ec 0x33ea 0x34be 0x346b 0x3434 0x33fd 0x33ed 0x33ea 0x34a3 0x3471 0x342b 0x33fc 0x33ee 0x33ea 0x3492 0x347a 0x3427 0x33fc 0x33ef 0x33ea 0x3490 0x347c 0x3429 0x33fc 0x33f1 0x33ed 0x3491 0x3471 0x342c 0x33fb 0x33f2 0x33f0 0x348f 0x3462 0x342a 0x33fc 0x33f2 0x33f0 0x348b 0x3459 0x3423 0x33fd 0x33f2 0x33f1 0x348b 0x3456 0x341d 0x33fe 0x33f1 0x33f1 0x348f 0x3452 0x3418 0x33fb 0x33ef 0x33ee 0x3492 0x3437 0x3414 0x33f7 0x33ed 0x33ea 0x3493 0x3439 0x3411 0x33f3 0x33e9 0x33e7 0x3490 0x343e 0x3410 0x33f0 0x33e5 0x33e3 0x348f 0x343c 0x340e 0x33ef 0x33e4 0x33e1 0x3495 0x3437 0x340d 0x33ef 0x33e3 0x33e1 0x349d 0x3427 0x340c 0x33ef 0x33e3 0x33e1 0x34a5 0x343c 0x340a 0x33ef 0x33e3 0x33e1 0x34b1 0x3443 0x3407 0x33ee 0x33e3 0x33df 0x34be 0x344b 0x3406 0x33ee 0x33e3 0x33df 0x34cd 0x3454 0x3406 0x33ee 0x33e4 0x33df 0x34df 0x345d 0x3406 0x33ee 0x33e5 0x33df 0x34f1 0x3468 0x3408 0x33ef 0x33e5 0x33e0 0x3506 0x3473 0x340e 0x33f0 0x33e5 0x33e1 0x351c 0x3482 0x3413 0x33f1 0x33e5 0x33e1 0x3536 0x3494 0x3418 0x33f2 0x33e5 0x33e2 0x3553 0x34a3 0x341d 0x33f3 0x33e5 0x33e2 0x356f 0x34b0 0x3423 0x33f3 0x33e5 0x33e2 0x358d 0x34bf 0x342a 0x33f3 0x33e6 0x33e3 0x35ae 0x34d7 0x3431 0x33f3 0x33e7 0x33e4 0x35d7 0x34fa 0x343a 0x33f6 0x33e8 0x33e6 0x3606 0x351e 0x3443 0x33f6 0x33e9 0x33e5 0x363f 0x354a 0x344c 0x33f4 0x33e6 0x33e2 0x3694 0x3588 0x3455 0x33f5 0x33e6 0x33e4 0x3698 0x3595 0x3443 0x33f6 0x33e8 0x33e7 0x36d5 0x35cd 0x3454 0x33fa 0x33ec 0x33eb 0x370f 0x35fa 0x3462 0x3400 0x33f1 0x33ed 0x3755 0x362e 0x3473 0x3404 0x33f4 0x33ef 0x379a 0x365f 0x348d 0x3409 0x33f4 0x33ef 0x37f5 0x3684 0x349e 0x3407 0x33ef 0x33eb 0x3879 0x36c2 0x34b0 0x3409 0x33ef 0x33ed 0x398d 0x3748 0x350e 0x3412 0x33f5 0x33f1 0x3c4d 0x37f7 0x35e4 0x3425 0x3400 0x33fc 0x3c4d 0x37f7 0x35e4 0x3425 0x3400 0x33fc 0x3c4d 0x37f7 0x35e4 0x3425 0x3400 0x33fc>;
	};

	qcom,pc-temp-y4-lut {
		qcom,lut-col-legend = <0xfffffff6 0x00 0x0a 0x19 0x28 0x32>;
		qcom,lut-row-legend = <0x2710 0x2648 0x2580 0x24b8 0x23f0 0x2328 0x2260 0x2198 0x20d0 0x2008 0x1f40 0x1e78 0x1db0 0x1ce8 0x1c20 0x1b58 0x1a90 0x19c8 0x1900 0x1838 0x1770 0x16a8 0x15e0 0x1518 0x1450 0x1388 0x12c0 0x11f8 0x1130 0x1068 0xfa0 0xed8 0xe10 0xd48 0xc80 0xbb8 0xaf0 0xa28 0x960 0x898 0x7d0 0x708 0x640 0x578 0x4b0 0x3e8 0x384 0x320 0x2bc 0x258 0x1f4 0x190 0x12c 0xc8 0x64 0x00>;
		qcom,lut-data = <0x4171 0x416b 0x40cc 0x406b 0x4059 0x405b 0x4202 0x417d 0x40d5 0x4069 0x4057 0x4059 0x4264 0x4191 0x40e1 0x4068 0x4055 0x4057 0x429d 0x41a6 0x40ec 0x4067 0x4054 0x4054 0x42b9 0x41b8 0x40f5 0x4067 0x4053 0x4053 0x42c0 0x41c8 0x40fa 0x4067 0x4052 0x4052 0x4299 0x41d4 0x40fc 0x4068 0x4053 0x4051 0x425f 0x41df 0x40fc 0x406a 0x4053 0x4050 0x4270 0x41e6 0x40fd 0x406c 0x4054 0x4050 0x42f7 0x41e9 0x40ff 0x4070 0x4056 0x4051 0x435b 0x41f1 0x4102 0x4075 0x4058 0x4052 0x4379 0x4239 0x4127 0x407d 0x405c 0x4054 0x438a 0x42c6 0x4158 0x4086 0x4060 0x4056 0x434f 0x42ef 0x4161 0x408c 0x4064 0x405a 0x4239 0x4264 0x415c 0x408f 0x4068 0x405e 0x4198 0x41c4 0x4158 0x4095 0x406d 0x4063 0x41a0 0x418c 0x415f 0x40ae 0x4075 0x4067 0x41ab 0x418d 0x4162 0x40d2 0x407f 0x406b 0x41ad 0x418c 0x4154 0x40ef 0x4094 0x4077 0x41ac 0x4189 0x4138 0x4109 0x40b6 0x408e 0x41a7 0x4181 0x4117 0x4112 0x40c3 0x409c 0x418e 0x4165 0x40ec 0x40e4 0x40b7 0x409f 0x416e 0x410c 0x40c4 0x40a3 0x40a3 0x409c 0x416c 0x4100 0x40af 0x4080 0x4089 0x4089 0x4174 0x4103 0x40a1 0x4065 0x405f 0x405f 0x417c 0x40f7 0x4097 0x405c 0x4050 0x404f 0x4181 0x40e4 0x4091 0x405b 0x4050 0x404f 0x4188 0x40ba 0x408b 0x405b 0x4050 0x404f 0x418f 0x40d9 0x4084 0x405d 0x4053 0x4052 0x4198 0x40df 0x407b 0x4061 0x405b 0x405a 0x41a0 0x40e6 0x4079 0x4064 0x4063 0x4063 0x41a8 0x40ef 0x407d 0x4066 0x406e 0x406f 0x41b3 0x40f9 0x4084 0x4067 0x4076 0x4079 0x41bf 0x4104 0x408c 0x406a 0x4076 0x407c 0x41ce 0x410e 0x4095 0x406d 0x4076 0x407e 0x41de 0x411a 0x40a1 0x4070 0x4075 0x407c 0x41ed 0x4131 0x40af 0x4071 0x4069 0x406b 0x41fd 0x4154 0x40be 0x4072 0x405e 0x405c 0x4212 0x4192 0x40cd 0x4072 0x405e 0x405d 0x422f 0x41c9 0x40db 0x4071 0x4060 0x4061 0x4249 0x41de 0x40e3 0x4071 0x4063 0x4067 0x4262 0x41e8 0x40e6 0x4079 0x406e 0x4075 0x4274 0x41f5 0x40e8 0x407b 0x406d 0x4074 0x4280 0x41fd 0x40e9 0x4075 0x4056 0x4053 0x426c 0x41da 0x40ee 0x4074 0x404d 0x4048 0x41d1 0x4180 0x40e5 0x406c 0x4053 0x4057 0x41e3 0x419b 0x40f7 0x407c 0x4069 0x4073 0x4200 0x41b5 0x4116 0x4090 0x4083 0x4097 0x421e 0x41e0 0x4150 0x40ad 0x40a7 0x40bd 0x422e 0x4205 0x418a 0x40d3 0x40c2 0x40c9 0x4232 0x4214 0x41ae 0x40b5 0x4080 0x4076 0x422e 0x420d 0x4192 0x40a9 0x4068 0x4062 0x425f 0x4211 0x41c6 0x40b9 0x406e 0x4065 0x43b2 0x4244 0x4216 0x40f0 0x409a 0x4089 0x43b2 0x4244 0x4216 0x40f0 0x409a 0x4089 0x43b2 0x4244 0x4216 0x40f0 0x409a 0x4089>;
	};

	qcom,pc-temp-y5-lut {
		qcom,lut-col-legend = <0xfffffff6 0x00 0x0a 0x19 0x28 0x32>;
		qcom,lut-row-legend = <0x2710 0x2648 0x2580 0x24b8 0x23f0 0x2328 0x2260 0x2198 0x20d0 0x2008 0x1f40 0x1e78 0x1db0 0x1ce8 0x1c20 0x1b58 0x1a90 0x19c8 0x1900 0x1838 0x1770 0x16a8 0x15e0 0x1518 0x1450 0x1388 0x12c0 0x11f8 0x1130 0x1068 0xfa0 0xed8 0xe10 0xd48 0xc80 0xbb8 0xaf0 0xa28 0x960 0x898 0x7d0 0x708 0x640 0x578 0x4b0 0x3e8 0x384 0x320 0x2bc 0x258 0x1f4 0x190 0x12c 0xc8 0x64 0x00>;
		qcom,lut-data = <0x3809 0x2e29 0x4119 0x4671 0x46de 0x41cb 0x347e 0x3262 0x439e 0x4818 0x472e 0x446e 0x32e7 0x36ab 0x458f 0x48ce 0x4711 0x46e8 0x32e6 0x3a88 0x46ee 0x48cd 0x46af 0x48fa 0x341d 0x3d7a 0x47bd 0x484e 0x462f 0x4a61 0x3632 0x3f04 0x47fd 0x478b 0x45b8 0x4adf 0x4058 0x3f33 0x475a 0x4607 0x4514 0x4a57 0x4d8c 0x3ec5 0x466c 0x43e8 0x445b 0x497c 0x4c62 0x3d96 0x4658 0x420a 0x4392 0x4904 0x3c1d 0x3a18 0x46e0 0x4038 0x4166 0x487c 0x325d 0x372c 0x4711 0x3e9c 0x3f7f 0x47af 0x3ee2 0x3852 0x4215 0x3d13 0x3e0c 0x45dd 0x50c9 0x3ccf 0x3bad 0x3bce 0x3cc1 0x4354 0x510d 0x43b5 0x3c0b 0x3af9 0x3c3a 0x40b2 0x4520 0x4f8e 0x415f 0x39a8 0x3c54 0x3daa 0x3e37 0x5af1 0x4744 0x38d8 0x3c72 0x3c73 0x4315 0x5d89 0x4dbe 0x380f 0x3b57 0x3d90 0x49ca 0x5785 0x53ac 0x3745 0x39ea 0x3ee2 0x489c 0x4f86 0x569b 0x3919 0x396f 0x3e22 0x3f60 0x4a13 0x58ab 0x415b 0x38cf 0x3b33 0x3951 0x45c7 0x5a01 0x4a2a 0x3901 0x3a2d 0x3840 0x4209 0x59df 0x549a 0x45b1 0x4382 0x377e 0x46bc 0x5929 0x5ce6 0x53a8 0x4e0c 0x35ae 0x43d6 0x591d 0x5c2e 0x53f9 0x4f2e 0x326c 0x3c67 0x5933 0x5710 0x511c 0x4ef9 0x3094 0x3896 0x595d 0x53d6 0x4e34 0x4e68 0x30ad 0x373a 0x5a25 0x52c2 0x4b32 0x4c3a 0x3112 0x44c0 0x5a51 0x5223 0x48bb 0x48ed 0x3127 0x3872 0x56a2 0x51f0 0x4759 0x44ab 0x315e 0x398e 0x4e87 0x51d6 0x461c 0x3f6b 0x3186 0x3aee 0x4905 0x51cf 0x461b 0x3dbc 0x3222 0x3c23 0x454f 0x523f 0x48d2 0x3e6a 0x32ef 0x3d67 0x431b 0x531b 0x4c88 0x3fbf 0x333b 0x3f74 0x4401 0x5539 0x5007 0x4369 0x335b 0x4242 0x469a 0x5915 0x539d 0x4a65 0x334c 0x4432 0x4830 0x5a8e 0x5548 0x4fb4 0x330b 0x41cb 0x4985 0x5ab2 0x560a 0x5435 0x32b3 0x3d69 0x4a61 0x5ab4 0x5666 0x56df 0x324a 0x38ad 0x4a00 0x57c4 0x555f 0x5631 0x31a7 0x34fe 0x48f9 0x50a9 0x5302 0x5472 0x310e 0x347b 0x47eb 0x4e03 0x51ff 0x5355 0x3061 0x33fb 0x467a 0x4f6c 0x520f 0x5212 0x3003 0x330e 0x4493 0x4e97 0x51dc 0x5082 0x3029 0x3206 0x4150 0x4599 0x4f8a 0x4e87 0x3143 0x320e 0x4014 0x4280 0x4986 0x4da5 0x34e9 0x33e5 0x3c21 0x45ba 0x4388 0x41bd 0x350a 0x338f 0x3fea 0x4493 0x419a 0x3ea9 0x350d 0x33f7 0x4043 0x456a 0x41b7 0x3b93 0x363b 0x34bf 0x3cf5 0x431d 0x4026 0x3a46 0x373c 0x36e4 0x4080 0x4342 0x3f03 0x39f7 0x3790 0x3758 0x419d 0x46f2 0x4118 0x3eac 0x36aa 0x3533 0x3c44 0x4a86 0x4631 0x4369 0x33f5 0x3346 0x355d 0x4c3c 0x4da4 0x4599 0x310a 0x339e 0x34e3 0x528c 0x61c6 0x62f3 0x310a 0x339e 0x34e3 0x528c 0x61c6 0x62f3 0x310a 0x339e 0x34e3 0x528c 0x61c6 0x62f3>;
	};

	qcom,pc-temp-y6-lut {
		qcom,lut-col-legend = <0xfffffff6 0x00 0x0a 0x19 0x28 0x32>;
		qcom,lut-row-legend = <0x2710 0x2648 0x2580 0x24b8 0x23f0 0x2328 0x2260 0x2198 0x20d0 0x2008 0x1f40 0x1e78 0x1db0 0x1ce8 0x1c20 0x1b58 0x1a90 0x19c8 0x1900 0x1838 0x1770 0x16a8 0x15e0 0x1518 0x1450 0x1388 0x12c0 0x11f8 0x1130 0x1068 0xfa0 0xed8 0xe10 0xd48 0xc80 0xbb8 0xaf0 0xa28 0x960 0x898 0x7d0 0x708 0x640 0x578 0x4b0 0x3e8 0x384 0x320 0x2bc 0x258 0x1f4 0x190 0x12c 0xc8 0x64 0x00>;
		qcom,lut-data = <0x18aa 0x15f5 0x149e 0x13de 0x13b4 0x13ad 0x1878 0x15f5 0x149f 0x13dd 0x13b4 0x13ad 0x1847 0x15f4 0x14a0 0x13dd 0x13b4 0x13ad 0x1819 0x15f1 0x14a0 0x13dd 0x13b4 0x13ad 0x17f2 0x15ed 0x149f 0x13dd 0x13b4 0x13ad 0x17d3 0x15e8 0x149e 0x13dd 0x13b5 0x13ad 0x17bd 0x15e1 0x149b 0x13dd 0x13b5 0x13ad 0x17aa 0x15da 0x1498 0x13de 0x13b6 0x13ae 0x1791 0x15d3 0x1496 0x13df 0x13b7 0x13ae 0x176e 0x15cb 0x1494 0x13e0 0x13b8 0x13af 0x175d 0x15c3 0x1494 0x13e1 0x13b9 0x13b0 0x1764 0x15ce 0x149c 0x13e5 0x13ba 0x13b1 0x176d 0x15e4 0x14a5 0x13e9 0x13bc 0x13b2 0x175c 0x15e7 0x14a5 0x13ea 0x13be 0x13b4 0x1706 0x15c9 0x149d 0x13eb 0x13c0 0x13b5 0x16d5 0x15a8 0x1499 0x13ec 0x13c2 0x13b7 0x16da 0x1597 0x149c 0x13f3 0x13c6 0x13b9 0x16e2 0x1591 0x14a0 0x13fe 0x13c9 0x13bd 0x16e0 0x158b 0x149a 0x1406 0x13d0 0x13c1 0x16d4 0x1586 0x148d 0x140e 0x13d8 0x13c8 0x16cc 0x1583 0x147f 0x1411 0x13dc 0x13cb 0x16c8 0x157e 0x146f 0x1401 0x13d7 0x13c9 0x16c6 0x1552 0x1462 0x13ec 0x13cf 0x13c6 0x16c6 0x155d 0x145d 0x13e0 0x13c5 0x13be 0x16c9 0x156d 0x1459 0x13d6 0x13b6 0x13af 0x16ce 0x156f 0x1458 0x13d3 0x13b0 0x13a9 0x16d7 0x1570 0x1458 0x13d3 0x13b0 0x13a9 0x16e4 0x154f 0x1458 0x13d4 0x13b1 0x13a9 0x16f4 0x157e 0x1457 0x13d5 0x13b2 0x13aa 0x1708 0x158e 0x1457 0x13d6 0x13b4 0x13ac 0x171d 0x15a0 0x1457 0x13d8 0x13b7 0x13ae 0x1733 0x15b4 0x145b 0x13d9 0x13bb 0x13b1 0x174a 0x15ca 0x1462 0x13da 0x13be 0x13b5 0x1764 0x15e4 0x146b 0x13dc 0x13bf 0x13b7 0x1781 0x1601 0x1476 0x13df 0x13bf 0x13b8 0x17a0 0x161f 0x1483 0x13e2 0x13bf 0x13b8 0x17bf 0x1640 0x1492 0x13e4 0x13bc 0x13b4 0x17e1 0x1662 0x14a2 0x13e6 0x13b9 0x13b0 0x1804 0x1687 0x14b4 0x13e7 0x13b9 0x13b0 0x182a 0x16b0 0x14c8 0x13e7 0x13bb 0x13b3 0x1853 0x16dd 0x14dd 0x13e9 0x13bd 0x13b6 0x187f 0x170f 0x14f3 0x13ee 0x13c1 0x13ba 0x18af 0x1745 0x150d 0x13f1 0x13c1 0x13ba 0x18e3 0x177e 0x152c 0x13f1 0x13b9 0x13af 0x191e 0x17b4 0x1553 0x13f5 0x13b8 0x13ae 0x190b 0x17b2 0x154f 0x13f5 0x13bc 0x13b5 0x1943 0x17e9 0x157c 0x13fe 0x13c6 0x13c0 0x197a 0x181d 0x15a4 0x1409 0x13d1 0x13cc 0x19bf 0x1856 0x15d2 0x1415 0x13dd 0x13d8 0x19ff 0x188c 0x1605 0x1424 0x13e5 0x13dc 0x1a4c 0x18b6 0x162b 0x141c 0x13ce 0x13c1 0x1abd 0x18ee 0x164c 0x141f 0x13c9 0x13be 0x1bb8 0x1961 0x16d6 0x1435 0x13d1 0x13c3 0x1e76 0x1a02 0x17c9 0x1462 0x13e8 0x13d7 0x1e76 0x1a02 0x17c9 0x1462 0x13e8 0x13d7 0x1e76 0x1a02 0x17c9 0x1462 0x13e8 0x13d7>;
	};
};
